# YTM32B1ME0 register map
Vendor: YTMicro; File version: 1.2
CPU: CM33 r0p4, little endian, MPU, FPU, 2 interrupt priority bits
Registers are 32-bit, read-write, reset 0x0 unless marked. A register's access mark holds for its fields unless they carry their own. Offsets are from the block's base; [hi:lo] are bit positions; {n}, {i} and the like mark numbered series.

## ACMP0 — Analog comparator module
Base 0x40043000; register names take the prefix ACMP0_
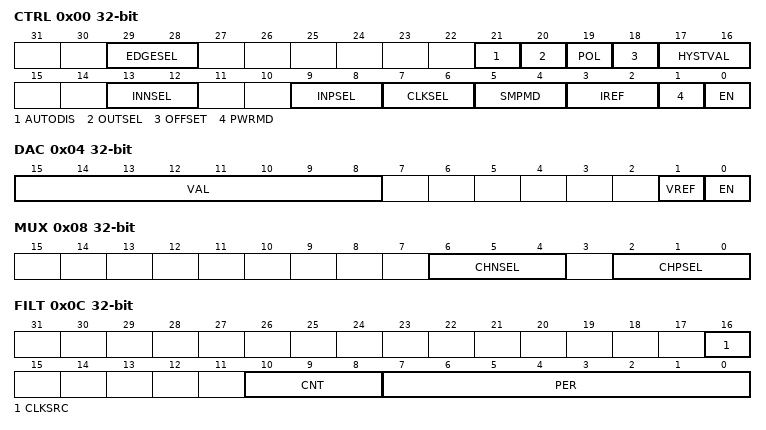
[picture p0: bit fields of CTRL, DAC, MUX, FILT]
0x00 CTRL
  [29:28] EDGESEL — Edge selection for interrupt/DMA
    0=No edge selection; 1=Select positive edge as interrupt/DMA condition, the positive edge flag is STS[OUTPF]; 2=Select negative edge as interrupt/DMA condition, the negative edge flag is STS[OUTNF]; 3=Select positive or negative edges as interrupt condition, not for DMA
  [21] AUTODIS — Automatic disable hard block when interrupt occurs or when waiting trigger in one-shot mode
    0=Not disable hard block automatically; 1=disable hard block automatically
  [20] OUTSEL — Output selection bit
    0=Send ACMP filtered output to pin; 1=Send ACMP output to pin directly
  [19] POL — Output polarity selection bit
    0=Not invert comparator output; 1=Invert comparator output
  [18] OFFSET — Comparator hard block offset control
    0=The hysteresis selected by HYSTVAL exists for INP crossing INN in the falling direction; 1=The hysteresis selected by HYSTVAL exists for both directions
  [17:16] HYSTVAL — Hysteresis level selection bit
    0=Comparator hard block output has no hysteresis internally; 1=Comparator hard block output has 20mV hysteresis internally; 2=Comparator hard block output has 40mV hysteresis internally
  [13:12] INNSEL — Negative input selection
    0=Select DAC output as comparator negative input; 1=Select one channel as comparator negative input
  [9:8] INPSEL — Positive input selection
    0=Select DAC output as comparator positive input; 1=Select one channel as comparator positive input
  [7:6] CLKSEL — Select the source of functional clock
    0=Functional clock is selected by IPC module (cannot be used in Powerdown mode); 1=Functional clock is from SIRC; 2=Functional clock is from SXOSC
  [5:4] SMPMD — Sample mode selection
    0=Common mode; 1=Trigger mode; 2=Window mode
  [3:2] IREF — Configure internal current level from minimum to maximum(00b->11b)
  [1] PWRMD — Power mode
    0=High speed mode; 1=Low power mode
  [0] EN — Module enable
    0=ACMP module is disabled; 1=ACMP module is enabled
0x04 DAC
  [15:8] VAL — DAC output voltage level selection from value 0 to 255
  [1] VREF — DAC voltage reference source selection
    0=select external reference voltage source; 1=select internal reference voltage source
  [0] EN — DAC enable
    0=DAC is disabled; 1=DAC is enabled
0x08 MUX
  [6:4] CHNSEL — Select one channel as negative Input of comparator
    {v}=Select channel {v} (v=0..7)
  [2:0] CHPSEL — Select one channel as positive Input of comparator
    {v}=Select channel {v} (v=0..7)
0x0C FILT
  [16] CLKSRC — Filter clock source
    0=Select functional clock for filter; 1=Select bus clock for filter
  [10:8] CNT — Digital filter counter
  [7:0] PER — Digital filter period
0x10 DMACR
  [0] EN — DMA enable
    0=DMA request is disabled; 1=DMA request is enabled
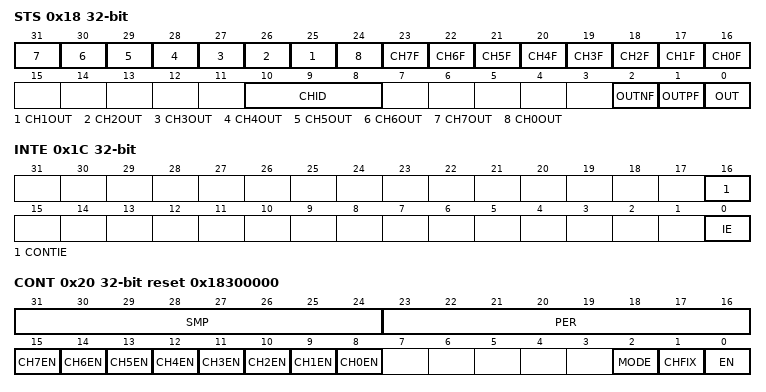
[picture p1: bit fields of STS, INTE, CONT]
0x18 STS
  [n+24] CH{n}OUT (n=1..7) — Channel {n} expected value configuration when continuous mode disabled and indicate the channel {n} result of comparator when continuous mode enabled
    0=Indicate the channel {n} result of comparator is 0 when continuous mode enabled; 1=Indicate the channel {n} result of comparator is 1 when continuous mode enabled
  [24] CH0OUT — Channel 0 expected value configuration when Continuous mode disabled and indicate the channel 0 result of comparator when continuous mode enabled
    0=Indicate the channel 0 result of comparator is 0 when continuous mode enabled; 1=Indicate the channel 0 result of comparator is 1 when continuous mode enabled
  [n+16] CH{n}F (n=0..7) — In continuous mode, the flag set when channel {n} result of comparator not match with its expected value. Write 1 to clear the flag
    0=Channel {n} result of comparator match with its expected value; 1=Channel {n} result of comparator not match with its expected value
  [10:8] CHID — Indicate current channel in continuous mode
  [2] OUTNF — Comparator output negative edge flag
  [1] OUTPF — Comparator output positive edge flag
  [0] OUT — Current comparator output
0x1C INTE
  [16] CONTIE — In continuous mode, interrupt occurs when INTE[CONTIE]=1 and STS[CHxF]=1
    0=Continuous mode interrupt is disabled; 1=Continuous mode interrupt is enabled
  [0] IE — Interrupt occurs when INTE[IE]=1 and STS[OUTNF]=1/STS[OUTPF]=1(depending on CTRL[EDGESEL])
    0=Interrupt is disabled; 1=Interrupt is enabled
0x20 CONT reset 0x18300000
  [31:24] SMP — After channel switch stabilization time, sample the comparator result
  [23:16] PER — Channel switch period
  [n+8] CH{n}EN (n=0..7) — Channel {n} participates in the continuous mode
    0=Channel {n} is disabled; 1=Channel {n} is enabled
  [2] MODE — Continuous mode control
    0=Loop mode; 1=one-shot mode
  [1] CHFIX — Fix channel in continuous mode
    0=Fix negative channel, continuous happens on positive channels; 1=Fix positive channel, continuous happens on negative channels
  [0] EN — Continuous Enable, ACMP module should be enabled
    0=Continuous mode is disabled; 1=Continuous mode is enabled
